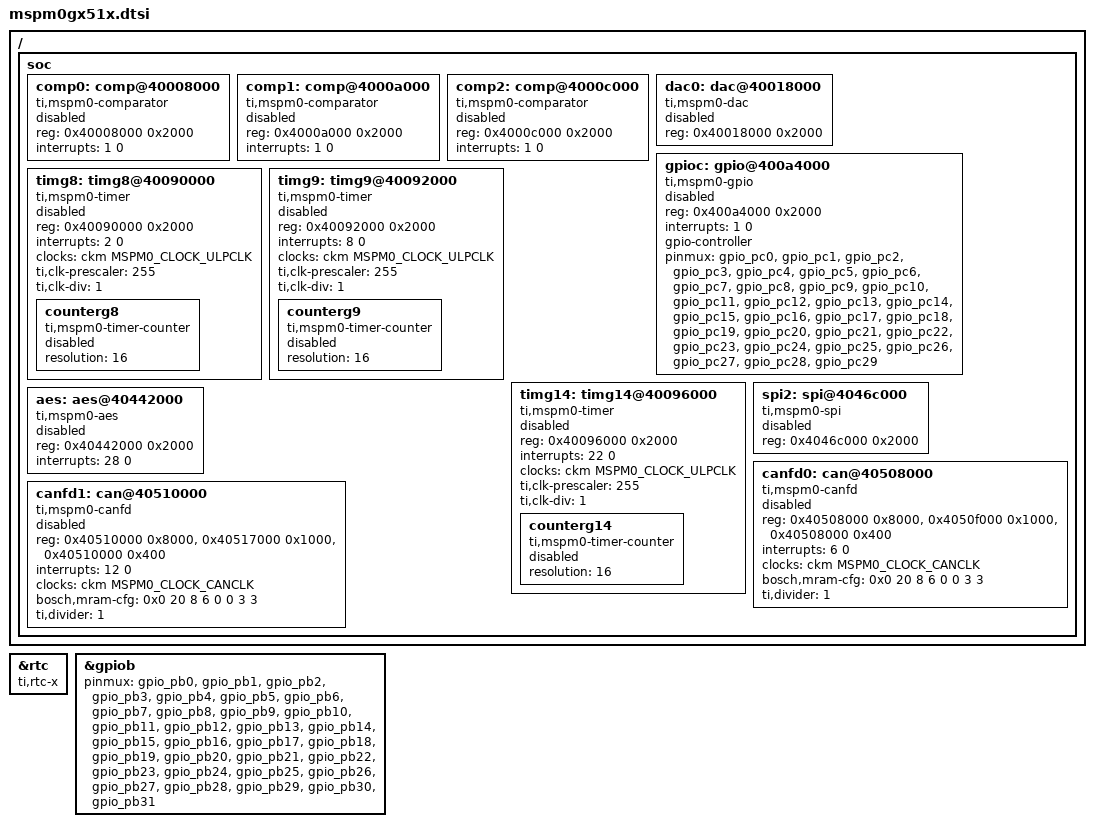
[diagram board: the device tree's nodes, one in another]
/*
 * Copyright (c) 2026 Texas Instruments
 *
 * SPDX-License-Identifier: Apache-2.0
 */

#include <ti/mspm0/g/mspm0g.dtsi>

/ {
	soc {
		comp0: comp@40008000 {
			compatible = "ti,mspm0-comparator";
			reg = <0x40008000 0x2000>;
			interrupts = <1 0>;
			status = "disabled";
		};

		comp1: comp@4000a000 {
			compatible = "ti,mspm0-comparator";
			reg = <0x4000a000 0x2000>;
			interrupts = <1 0>;
			status = "disabled";
		};

		comp2: comp@4000c000 {
			compatible = "ti,mspm0-comparator";
			reg = <0x4000c000 0x2000>;
			interrupts = <1 0>;
			status = "disabled";
		};

		dac0: dac@40018000 {
			compatible = "ti,mspm0-dac";
			reg = <0x40018000 0x2000>;
			status = "disabled";
			#io-channel-cells = <1>;
		};

		gpioc: gpio@400a4000 {
			compatible = "ti,mspm0-gpio";
			reg = <0x400a4000 0x2000>;
			interrupts = <1 0>;
			status = "disabled";
			gpio-controller;
			#gpio-cells = <2>;
		};

		timg8: timg8@40090000 {
			compatible = "ti,mspm0-timer";
			reg = <0x40090000 0x2000>;
			interrupts = <2 0>;
			clocks = <&ckm MSPM0_CLOCK_ULPCLK>;
			ti,clk-prescaler = <255>;
			ti,clk-div = <1>;
			status = "disabled";

			counterg8: counterg8 {
				compatible = "ti,mspm0-timer-counter";
				resolution = <16>;
				status = "disabled";
			};
		};

		timg9: timg9@40092000 {
			compatible = "ti,mspm0-timer";
			reg = <0x40092000 0x2000>;
			interrupts = <8 0>;
			clocks = <&ckm MSPM0_CLOCK_ULPCLK>;
			ti,clk-prescaler = <255>;
			ti,clk-div = <1>;
			status = "disabled";

			counterg9: counterg9 {
				compatible = "ti,mspm0-timer-counter";
				resolution = <16>;
				status = "disabled";
			};
		};

		timg14: timg14@40096000 {
			compatible = "ti,mspm0-timer";
			reg = <0x40096000 0x2000>;
			interrupts = <22 0>;
			clocks = <&ckm MSPM0_CLOCK_ULPCLK>;
			ti,clk-prescaler = <255>;
			ti,clk-div = <1>;
			status = "disabled";

			counterg14: counterg14 {
				compatible = "ti,mspm0-timer-counter";
				resolution = <16>;
				status = "disabled";
			};
		};

		spi2: spi@4046c000 {
			compatible = "ti,mspm0-spi";
			reg = <0x4046c000 0x2000>;
			status = "disabled";
		};

		aes: aes@40442000 {
			compatible = "ti,mspm0-aes";
			reg = <0x40442000 0x2000>;
			interrupts = <28 0>;
			status = "disabled";
		};

		canfd0: can@40508000 {
			compatible = "ti,mspm0-canfd";
			reg = <0x40508000 0x8000>, <0x4050f000 0x1000>, <0x40508000 0x400>;
			reg-names = "ti_canfd", "m_can", "message_ram";
			interrupts = <6 0>;
			clocks = <&ckm MSPM0_CLOCK_CANCLK>;
			bosch,mram-cfg = <0x0 20 8 6 0 0 3 3>;
			ti,divider = <1>;
			status = "disabled";
		};

		canfd1: can@40510000 {
			compatible = "ti,mspm0-canfd";
			reg = <0x40510000 0x8000>, <0x40517000 0x1000>, <0x40510000 0x400>;
			reg-names = "ti_canfd", "m_can", "message_ram";
			interrupts = <12 0>;
			clocks = <&ckm MSPM0_CLOCK_CANCLK>;
			bosch,mram-cfg = <0x0 20 8 6 0 0 3 3>;
			ti,divider = <1>;
			status = "disabled";
		};
	};
};

&rtc {
	ti,rtc-x;
};

&gpiob {
	pinmux = <&gpio_pb0>,
		 <&gpio_pb1>,
		 <&gpio_pb2>,
		 <&gpio_pb3>,
		 <&gpio_pb4>,
		 <&gpio_pb5>,
		 <&gpio_pb6>,
		 <&gpio_pb7>,
		 <&gpio_pb8>,
		 <&gpio_pb9>,
		 <&gpio_pb10>,
		 <&gpio_pb11>,
		 <&gpio_pb12>,
		 <&gpio_pb13>,
		 <&gpio_pb14>,
		 <&gpio_pb15>,
		 <&gpio_pb16>,
		 <&gpio_pb17>,
		 <&gpio_pb18>,
		 <&gpio_pb19>,
		 <&gpio_pb20>,
		 <&gpio_pb21>,
		 <&gpio_pb22>,
		 <&gpio_pb23>,
		 <&gpio_pb24>,
		 <&gpio_pb25>,
		 <&gpio_pb26>,
		 <&gpio_pb27>,
		 <&gpio_pb28>,
		 <&gpio_pb29>,
		 <&gpio_pb30>,
		 <&gpio_pb31>;
};

&gpioc {
	pinmux = <&gpio_pc0>,
		 <&gpio_pc1>,
		 <&gpio_pc2>,
		 <&gpio_pc3>,
		 <&gpio_pc4>,
		 <&gpio_pc5>,
		 <&gpio_pc6>,
		 <&gpio_pc7>,
		 <&gpio_pc8>,
		 <&gpio_pc9>,
		 <&gpio_pc10>,
		 <&gpio_pc11>,
		 <&gpio_pc12>,
		 <&gpio_pc13>,
		 <&gpio_pc14>,
		 <&gpio_pc15>,
		 <&gpio_pc16>,
		 <&gpio_pc17>,
		 <&gpio_pc18>,
		 <&gpio_pc19>,
		 <&gpio_pc20>,
		 <&gpio_pc21>,
		 <&gpio_pc22>,
		 <&gpio_pc23>,
		 <&gpio_pc24>,
		 <&gpio_pc25>,
		 <&gpio_pc26>,
		 <&gpio_pc27>,
		 <&gpio_pc28>,
		 <&gpio_pc29>;
};
